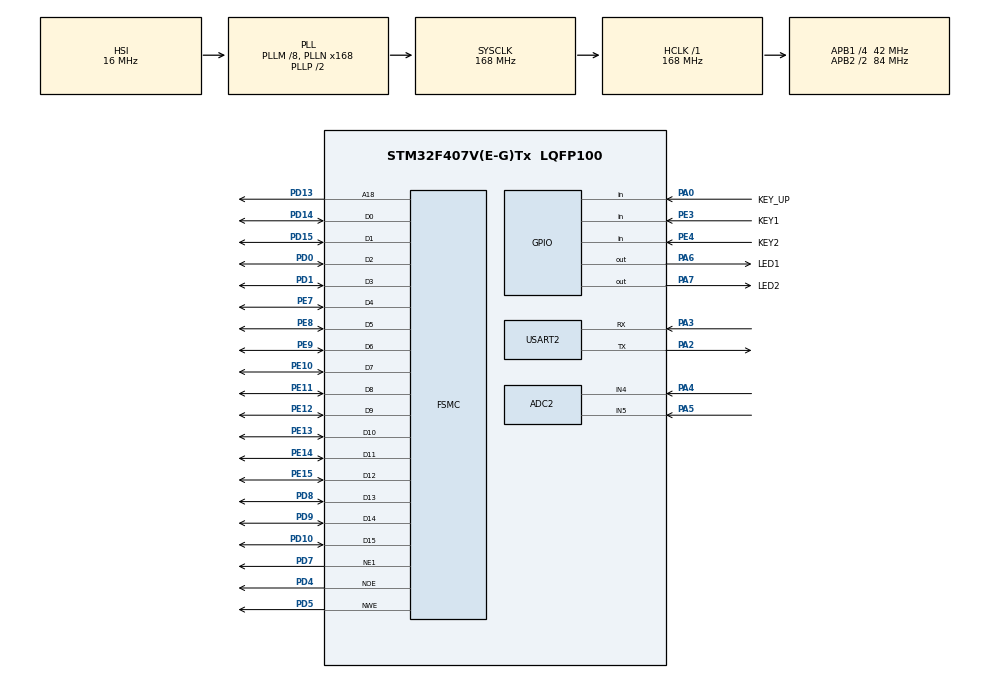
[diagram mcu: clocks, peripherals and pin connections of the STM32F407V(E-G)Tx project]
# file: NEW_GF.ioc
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ADC2.Channel-0\#ChannelRegularConversion=ADC_CHANNEL_4
ADC2.Channel-1\#ChannelRegularConversion=ADC_CHANNEL_5
ADC2.ContinuousConvMode=DISABLE
ADC2.DMAContinuousRequests=ENABLE
ADC2.ExternalTrigConv=ADC_EXTERNALTRIGCONV_T2_CC2
ADC2.ExternalTrigConvEdge=ADC_EXTERNALTRIGCONVEDGE_FALLING
ADC2.InjNumberOfConversion=0
ADC2.NbrOfConversion=2
ADC2.NbrOfConversionFlag=1
ADC2.Rank-0\#ChannelRegularConversion=1
ADC2.Rank-1\#ChannelRegularConversion=2
ADC2.SamplingTime-0\#ChannelRegularConversion=ADC_SAMPLETIME_56CYCLES
ADC2.SamplingTime-1\#ChannelRegularConversion=ADC_SAMPLETIME_56CYCLES
Dma.ADC2.0.Direction=DMA_PERIPH_TO_MEMORY
Dma.ADC2.0.FIFOMode=DMA_FIFOMODE_DISABLE
Dma.ADC2.0.Instance=DMA2_Stream2
Dma.ADC2.0.MemDataAlignment=DMA_MDATAALIGN_HALFWORD
Dma.ADC2.0.MemInc=DMA_MINC_ENABLE
Dma.ADC2.0.Mode=DMA_CIRCULAR
Dma.ADC2.0.PeriphDataAlignment=DMA_PDATAALIGN_HALFWORD
Dma.ADC2.0.PeriphInc=DMA_PINC_DISABLE
Dma.ADC2.0.Priority=DMA_PRIORITY_LOW
Dma.Request0=ADC2
Mcu.Family=STM32F4
Mcu.Name=STM32F407V(E-G)Tx
Mcu.Package=LQFP100
NVIC.DMA2_Stream2_IRQn=true\:0\:0\:false\:false\:true\:false\:true
NVIC.PriorityGroup=NVIC_PRIORITYGROUP_4
PA0-WKUP.GPIO_Label=KEY_UP
PA0-WKUP.Signal=GPIO_Input
PA13.Mode=Serial_Wire
PA13.Signal=SYS_JTMS-SWDIO
PA14.Mode=Serial_Wire
PA14.Signal=SYS_JTCK-SWCLK
PA2.Mode=Asynchronous
PA2.Signal=USART2_TX
PA3.Mode=Asynchronous
PA3.Signal=USART2_RX
PA4.Signal=ADCx_IN4
PA5.Signal=ADCx_IN5
PA6.GPIO_Label=LED1
PA6.Signal=GPIO_Output
PA7.GPIO_Label=LED2
PA7.Signal=GPIO_Output
PD0.Mode=16b-d1
PD0.Signal=FSMC_D2
PD1.Mode=16b-d1
PD1.Signal=FSMC_D3
PD10.Mode=16b-d1
PD10.Signal=FSMC_D15
PD13.Mode=A18_1
PD13.Signal=FSMC_A18
PD14.Mode=16b-d1
PD14.Signal=FSMC_D0
PD15.Mode=16b-d1
PD15.Signal=FSMC_D1
PD4.Mode=Lcd1
PD4.Signal=FSMC_NOE
PD5.Mode=Lcd1
PD5.Signal=FSMC_NWE
PD7.Mode=NorPsramChipSelect1_1
PD7.Signal=FSMC_NE1
PD8.Mode=16b-d1
PD8.Signal=FSMC_D13
PD9.Mode=16b-d1
PD9.Signal=FSMC_D14
PE10.Mode=16b-d1
PE10.Signal=FSMC_D7
PE11.Mode=16b-d1
PE11.Signal=FSMC_D8
PE12.Mode=16b-d1
PE12.Signal=FSMC_D9
PE13.Mode=16b-d1
PE13.Signal=FSMC_D10
PE14.Mode=16b-d1
PE14.Signal=FSMC_D11
PE15.Mode=16b-d1
PE15.Signal=FSMC_D12
PE3.GPIO_Label=KEY1
PE3.Signal=GPIO_Input
PE4.GPIO_Label=KEY2
PE4.Signal=GPIO_Input
PE7.Mode=16b-d1
PE7.Signal=FSMC_D4
PE8.Mode=16b-d1
PE8.Signal=FSMC_D5
PE9.Mode=16b-d1
PE9.Signal=FSMC_D6
PH0-OSC_IN.Mode=HSE-External-Oscillator
PH0-OSC_IN.Signal=RCC_OSC_IN
PH1-OSC_OUT.Mode=HSE-External-Oscillator
PH1-OSC_OUT.Signal=RCC_OSC_OUT
ProjectManager.HeapSize=0x200
ProjectManager.StackSize=0x400
ProjectManager.TargetToolchain=Makefile
RCC.48MHZClocksFreq_Value=84000000
RCC.AHBFreq_Value=168000000
RCC.APB1CLKDivider=RCC_HCLK_DIV4
RCC.APB1Freq_Value=42000000
RCC.APB1TimFreq_Value=84000000
RCC.APB2CLKDivider=RCC_HCLK_DIV2
RCC.APB2Freq_Value=84000000
RCC.APB2TimFreq_Value=168000000
RCC.CortexFreq_Value=168000000
RCC.HCLKFreq_Value=168000000
RCC.HSE_VALUE=25000000
RCC.HSI_VALUE=16000000
RCC.LSE_VALUE=32768
RCC.PLLM=8
RCC.PLLN=168
RCC.SYSCLKFreq_VALUE=168000000
RCC.SYSCLKSource=RCC_SYSCLKSOURCE_PLLCLK
RCC.VCOOutputFreq_Value=336000000
SH.ADCx_IN4.0=ADC2_IN4,IN4
SH.ADCx_IN5.0=ADC2_IN5,IN5
TIM2.Channel-PWM\ Generation2\ No\ Output=TIM_CHANNEL_2
TIM2.Period=9999
TIM2.Prescaler=1679
TIM2.Pulse-PWM\ Generation2\ No\ Output=50
USART2.VirtualMode=VM_ASYNC
VP_TIM2_VS_no_output2.Mode=PWM Generation2 No Output
board=custom

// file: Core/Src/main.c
/* USER CODE BEGIN Header */
/**
  ******************************************************************************
  * @file           : main.c
  * @brief          : Main program body
  ******************************************************************************
  * @attention
  *
  * <h2><center>&copy; Copyright (c) 2024 STMicroelectronics.
  * All rights reserved.</center></h2>
  *
  * This software component is licensed by ST under BSD 3-Clause license,
  * the "License"; You may not use this file except in compliance with the
  * License. You may obtain a copy of the License at:
  *                        opensource.org/licenses/BSD-3-Clause
  *
  ******************************************************************************
  */
/* USER CODE END Header */
#include "main.h"
#include "adc.h"
#include "dma.h"
#include "tim.h"
#include "usart.h"
#include "gpio.h"
#include "fsmc.h"

/* USER CODE BEGIN Includes */
#include "stdio.h"
#include "LCD.h"
#include "servo.h"
/* USER CODE END Includes */

void SystemClock_Config(void);

int main(void)
{

  /* MCU Configuration--------------------------------------------------------*/

  /* Reset of all peripherals, Initializes the Flash interface and the Systick. */
  HAL_Init();

  /* Configure the system clock */
  SystemClock_Config();

  /* Initialize all configured peripherals */
  MX_GPIO_Init();
  MX_DMA_Init();
  MX_ADC2_Init();
  MX_USART2_UART_Init();
  MX_TIM2_Init();
  MX_FSMC_Init();
  /* USER CODE BEGIN 2 */
  servo_init();

  LCD_Init();
  LCD_DisplayOn();
  HAL_Delay(1);
  /* USER CODE END 2 */

  /* Infinite loop */
  /* USER CODE BEGIN WHILE */
  while (1)
  {
    HAL_GPIO_WritePin(LED2_GPIO_Port,LED2_Pin,GPIO_PIN_SET);
    //HAL_UART_Transmit(&huart2,"11/r/n",2,0xff);
    LCD_Fill(1,1,20,20,BLACK);
    /* USER CODE END WHILE */

    /* USER CODE BEGIN 3 */
    HAL_GPIO_WritePin(LED2_GPIO_Port,LED2_Pin,GPIO_PIN_RESET);
  }
  /* USER CODE END 3 */
}

void SystemClock_Config(void)
{
  RCC_OscInitTypeDef RCC_OscInitStruct = {0};
  RCC_ClkInitTypeDef RCC_ClkInitStruct = {0};

  /** Configure the main internal regulator output voltage
  */
  __HAL_RCC_PWR_CLK_ENABLE();
  __HAL_PWR_VOLTAGESCALING_CONFIG(PWR_REGULATOR_VOLTAGE_SCALE1);
  /** Initializes the RCC Oscillators according to the specified parameters
  * in the RCC_OscInitTypeDef structure.
  */
  RCC_OscInitStruct.OscillatorType = RCC_OSCILLATORTYPE_HSI;
  RCC_OscInitStruct.HSIState = RCC_HSI_ON;
  RCC_OscInitStruct.HSICalibrationValue = RCC_HSICALIBRATION_DEFAULT;
  RCC_OscInitStruct.PLL.PLLState = RCC_PLL_ON;
  RCC_OscInitStruct.PLL.PLLSource = RCC_PLLSOURCE_HSI;
  RCC_OscInitStruct.PLL.PLLM = 8;
  RCC_OscInitStruct.PLL.PLLN = 168;
  RCC_OscInitStruct.PLL.PLLP = RCC_PLLP_DIV2;
  RCC_OscInitStruct.PLL.PLLQ = 4;
  if (HAL_RCC_OscConfig(&RCC_OscInitStruct) != HAL_OK)
  {
    Error_Handler();
  }
  /** Initializes the CPU, AHB and APB buses clocks
  */
  RCC_ClkInitStruct.ClockType = RCC_CLOCKTYPE_HCLK|RCC_CLOCKTYPE_SYSCLK
                              |RCC_CLOCKTYPE_PCLK1|RCC_CLOCKTYPE_PCLK2;
  RCC_ClkInitStruct.SYSCLKSource = RCC_SYSCLKSOURCE_PLLCLK;
  RCC_ClkInitStruct.AHBCLKDivider = RCC_SYSCLK_DIV1;
  RCC_ClkInitStruct.APB1CLKDivider = RCC_HCLK_DIV4;
  RCC_ClkInitStruct.APB2CLKDivider = RCC_HCLK_DIV2;

  if (HAL_RCC_ClockConfig(&RCC_ClkInitStruct, FLASH_LATENCY_5) != HAL_OK)
  {
    Error_Handler();
  }
}

void Error_Handler(void)
{
  __disable_irq();
  while (1)
  {
  }
}

/************************ (C) COPYRIGHT STMicroelectronics *****END OF FILE****/
